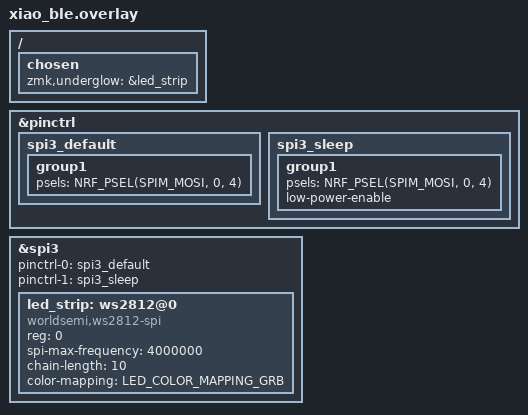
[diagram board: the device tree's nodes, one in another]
/ {
    chosen {
        zmk,underglow = &led_strip;
    };
};

&pinctrl {
    spi3_default: spi3_default {
        group1 {
            /* MOSI = D4 (P0.04) に割り当て。D5なら (0, 5) */
            psels = <NRF_PSEL(SPIM_MOSI, 0, 4)>;
        };
    };
    spi3_sleep: spi3_sleep {
        group1 {
            psels = <NRF_PSEL(SPIM_MOSI, 0, 4)>;
            low-power-enable;
        };
    };
};

&spi3 {
    status = "okay";
    pinctrl-0 = <&spi3_default>;
    pinctrl-1 = <&spi3_sleep>;
    pinctrl-names = "default", "sleep";

    /* SK6812(WS2812互換) 10個 */
    led_strip: ws2812@0 {
        compatible = "worldsemi,ws2812-spi";
        reg = <0>;
        spi-max-frequency = <4000000>;
        chain-length = <10>;
        /* 色が変なら GRB ⇄ RGB 等を入れ替え */
        color-mapping = <LED_COLOR_MAPPING_GRB>;
        status = "okay";
    };
}
